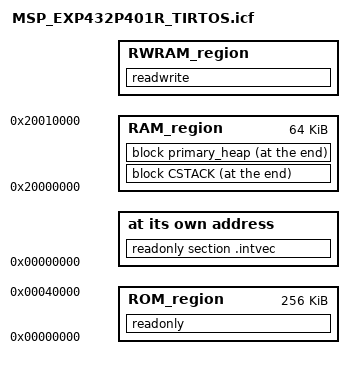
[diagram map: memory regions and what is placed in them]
/*
 * Copyright (c) 2017-2019, Texas Instruments Incorporated
 * All rights reserved.
 *
 * Redistribution and use in source and binary forms, with or without
 * modification, are permitted provided that the following conditions
 * are met:
 *
 * *  Redistributions of source code must retain the above copyright
 *    notice, this list of conditions and the following disclaimer.
 *
 * *  Redistributions in binary form must reproduce the above copyright
 *    notice, this list of conditions and the following disclaimer in the
 *    documentation and/or other materials provided with the distribution.
 *
 * *  Neither the name of Texas Instruments Incorporated nor the names of
 *    its contributors may be used to endorse or promote products derived
 *    from this software without specific prior written permission.
 *
 * THIS SOFTWARE IS PROVIDED BY THE COPYRIGHT HOLDERS AND CONTRIBUTORS "AS IS"
 * AND ANY EXPRESS OR IMPLIED WARRANTIES, INCLUDING, BUT NOT LIMITED TO,
 * THE IMPLIED WARRANTIES OF MERCHANTABILITY AND FITNESS FOR A PARTICULAR
 * PURPOSE ARE DISCLAIMED. IN NO EVENT SHALL THE COPYRIGHT OWNER OR
 * CONTRIBUTORS BE LIABLE FOR ANY DIRECT, INDIRECT, INCIDENTAL, SPECIAL,
 * EXEMPLARY, OR CONSEQUENTIAL DAMAGES (INCLUDING, BUT NOT LIMITED TO,
 * PROCUREMENT OF SUBSTITUTE GOODS OR SERVICES; LOSS OF USE, DATA, OR PROFITS;
 * OR BUSINESS INTERRUPTION) HOWEVER CAUSED AND ON ANY THEORY OF LIABILITY,
 * WHETHER IN CONTRACT, STRICT LIABILITY, OR TORT (INCLUDING NEGLIGENCE OR
 * OTHERWISE) ARISING IN ANY WAY OUT OF THE USE OF THIS SOFTWARE,
 * EVEN IF ADVISED OF THE POSSIBILITY OF SUCH DAMAGE.
 */

define symbol __intvec_start__ = 0x00000000;
/*-Memory Regions-*/
define symbol ROM_start__   = 0x00000000;
define symbol ROM_end__     = 0x00040000;
define symbol RAM_start__   = 0x20000000;
define symbol RAM_end__     = 0x20010000;

define memory mem with size = 4G;
define region ROM_region   = mem:[from ROM_start__   to ROM_end__];
define region RAM_region   = mem:[from RAM_start__   to RAM_end__];

define symbol STACKSIZE = 1024;
define block CSTACK with alignment = 8, size = STACKSIZE  { section .stack };
do not initialize { section .stack };
do not initialize  { section .noinit };

place at address mem:__intvec_start__ { readonly section .intvec };
place in ROM_region   { readonly };

place at end of RAM_region  { block CSTACK };

/* HeapMem Primary Heap configuration */
define symbol HEAPSIZE = 0x8000;
define block primary_heap with size = HEAPSIZE {};

/* place heap just before CSTACK */
place at end of RAM_region { block primary_heap };

/* define buffer start and end symbols for HeapMem Primary Heap */
define exported symbol __primary_heap_end__ = end(RAM_region) - STACKSIZE;
define exported symbol __primary_heap_start__ = __primary_heap_end__ - HEAPSIZE;

/* Ensure RW data is not placed in stack or heap blocks */
define region RWRAM_region   = mem:[from RAM_start__   to __primary_heap_start__];
place in RWRAM_region   { readwrite };
initialize by copy { readwrite };
